# CH641 register map
Vendor: WCH Ltd.; File version: 1.0
Registers are 32-bit, read-write, reset 0x0 unless marked. A register's access mark holds for its fields unless they carry their own. Offsets are from the block's base; [hi:lo] are bit positions; {n}, {i} and the like mark numbered series.

## USART1 — Universal synchronous asynchronous receiver transmitter
Base 0x40013800
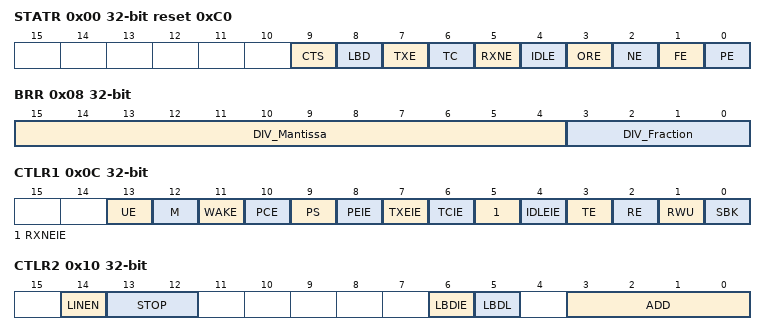
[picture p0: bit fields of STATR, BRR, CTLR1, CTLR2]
0x00 STATR access per field reset 0xC0 — Status register
  [9] CTS rw — CTS flag
  [8] LBD rw — LIN break detection flag
  [7] TXE ro — Transmit data register empty
  [6] TC rw — Transmission complete
  [5] RXNE rw — Read data register not empty
  [4] IDLE ro — IDLE line detected
  [3] ORE ro — Overrun error
  [2] NE ro — Noise error flag
  [1] FE ro — Framing error
  [0] PE ro — Parity error
0x04 DATAR — Data register
  [8:0] DR — Data value
0x08 BRR — Baud rate register
  [15:4] DIV_Mantissa — mantissa of USARTDIV
  [3:0] DIV_Fraction — fraction of USARTDIV
0x0C CTLR1 — Control register 1
  [13] UE — USART enable
  [12] M — Word length
  [11] WAKE — Wakeup method
  [10] PCE — Parity control enable
  [9] PS — Parity selection
  [8] PEIE — PE interrupt enable
  [7] TXEIE — TXE interrupt enable
  [6] TCIE — Transmission complete interrupt enable
  [5] RXNEIE — RXNE interrupt enable
  [4] IDLEIE — IDLE interrupt enable
  [3] TE — Transmitter enable
  [2] RE — Receiver enable
  [1] RWU — Receiver wakeup
  [0] SBK — Send break
0x10 CTLR2 — Control register 2
  [14] LINEN — LIN mode enable
  [13:12] STOP — STOP bits
  [6] LBDIE — LIN break detection interrupt enable
  [5] LBDL — lin break detection length
  [3:0] ADD — Address of the USART node
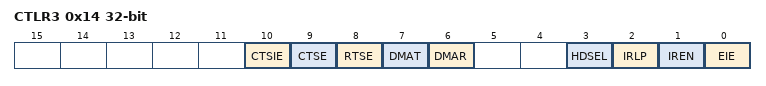
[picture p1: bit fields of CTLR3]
0x14 CTLR3 — Control register 3
  [10] CTSIE — CTS interrupt enable
  [9] CTSE — CTS enable
  [8] RTSE — RTS enable
  [7] DMAT — DMA enable transmitter
  [6] DMAR — DMA enable receiver
  [3] HDSEL — Half-duplex selection
  [2] IRLP — IrDA low-power
  [1] IREN — IrDA mode enable
  [0] EIE — Error interrupt enable
0x18 GPR — Guard time and prescaler register
  [7:0] PSC — Prescaler value

## DBG — Debug support
Base 0xE000D000
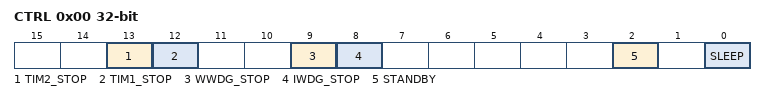
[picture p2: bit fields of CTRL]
0x00 CTRL — DBGMCU_CFGR1
  [13] TIM2_STOP
  [12] TIM1_STOP
  [9] WWDG_STOP
  [8] IWDG_STOP
  [2] STANDBY — Debug standby mode
  [0] SLEEP — Debug Sleep mode

## ESIG — Device electronic signature
Base 0x1FFFF7E0
0x00 FLACAP 16-bit ro — Flash capacity register
  [15:0] F_SIZE_15_0 — Flash size
{0x4+4i} UNIID{i} ro (i=1..3) — Unique identity {i}
  [31:0] U_ID_{32i-1}_{32i-32} — Unique identity[{32i-1}:{32i-32}]

## FLASH
Base 0x40022000
0x00 ACTLR — Flash key register
  [1:0] LATENCY — Number of FLASH wait states
0x04 KEYR wo — Flash key register
  [31:0] KEYR — FPEC key
0x08 OBTKEYR wo — Flash option key register
  [31:0] OBKEYR — Option byte key
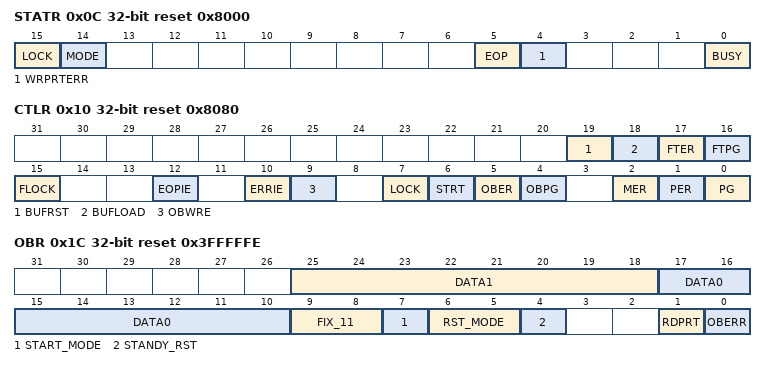
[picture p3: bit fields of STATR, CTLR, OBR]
0x0C STATR access per field reset 0x8000 — Status register
  [15] LOCK rw — BOOT lock
  [14] MODE rw — BOOT mode
  [5] EOP rw — End of operation
  [4] WRPRTERR rw — Write protection error
  [0] BUSY ro
0x10 CTLR reset 0x8080 — Control register
  [19] BUFRST — Buffer reset
  [18] BUFLOAD — Buffer load
  [17] FTER — Fast erase
  [16] FTPG — Fast programming
  [15] FLOCK — Fast programmable lock
  [12] EOPIE — End of operation interrupt enable
  [10] ERRIE — Error interrupt enable
  [9] OBWRE — Option bytes write enable
  [7] LOCK
  [6] STRT — Start
  [5] OBER — Option byte erase
  [4] OBPG — Option byte programming
  [2] MER — Mass Erase
  [1] PER — Page Erase
  [0] PG — Programming
0x14 ADDR wo — Flash address register
  [31:0] FAR — Flash Address
0x1C OBR ro reset 0x3FFFFFE — Option byte register
  [25:18] DATA1
  [17:10] DATA0
  [9:8] FIX_11
  [7] START_MODE — STARTUP area selection
  [6:5] RST_MODE — CFG_RST_MODE
  [4] STANDY_RST
  [1] RDPRT — Read protection
  [0] OBERR — Option byte error
0x20 WPR ro reset 0xFFFFFFFF — Write protection register
  [15:0] WRP — Write protect
0x24 MODEKEYR wo — Mode select register
  [31:0] MODEKEYR — Mode select
0x28 BOOT_MODEKEYP wo — Boot mode key register
  [31:0] MODEKEYR — Boot mode key
